# QN908XC register map
Vendor: nxp.com; File version: 1.0
CPU: CM4 r0p1, little endian, no MPU, no FPU, 0x3 interrupt priority bits, 0x0 interrupts
Registers are 32-bit, read-write, reset 0x0 unless marked. A register's access mark holds for its fields unless they carry their own. Offsets are from the block's base; [hi:lo] are bit positions; {n}, {i} and the like mark numbered series; 'fields as' and 'values as' point back to an identical list; <NAME> marks a mode.

## ADC
Base 0x40007000
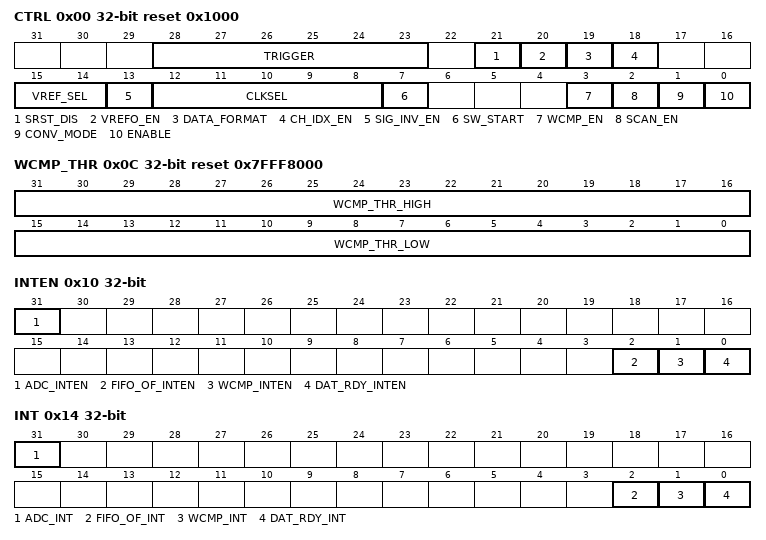
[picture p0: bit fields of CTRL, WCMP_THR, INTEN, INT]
0x00 CTRL reset 0x1000 (reset mask 0x1FBCFF0F) — ADC control register
  [28:23] TRIGGER — Adc start trigger. 0 to 31 PA00 to PA31; 32 to 34 GPIOB0 to GPIOB2; 35, software trigger; 36, rng trigger; 56 to 59, timer 0 to timer 3; 60 to 63 pwm 0 to pwm 3
  [21] SRST_DIS — 1 to disable adc reset.
  [20] VREFO_EN — 1 to enable bandgap out-chip capacitor
  [19] DATA_FORMAT — Data output format. When DATA_FORMAT ==0, When CH_IDX_EN ==0, the ADC_DATA[31:0] is adc data, signed data, 31 bit frac. When CH_IDX_EN ==1, the ADC_DATA[4:0] is channel output, {ADC_DATA[31:5],5'h0} is adc data, signed data, 31 bit frac. When DATA_FORMAT ==1, When CH_IDX_EN ==0, the ADC_DATA[22:0] is adc data, signed data, 22 bit frac. When CH_IDX_EN ==1, the ADC_DATA[31:27] is channel output, ADC_DATA[22:0] is adc data, signed data, 22 bit frac.
  [18] CH_IDX_EN — 1 to append channel index in data result to be used in scan mode
  [15:14] VREF_SEL — Sigma-Delta ADC Reference source selection.
    0=INT_1P2V (Internal vref 1.2V); 1=EXT_DRV (External VREF); 2=EXT_NO_DRV (Vext without driver); 3=VCC
  [13] SIG_INV_EN — 1 to invert Signma-Delta input signal
  [12:8] CLKSEL — Sigma-Delta ADC clock select
    0=CLKSEL_31P25K (31P25K); 4=CLKSEL_62P5K (62P5K); 8=CLKSEL_125K (125K); 12=CLKSEL_250K (250K); 16=CLKSEL_500K (500K); 20=CLKSEL_1M (1M); 24=CLKSEL_2M (2M); 29=CLKSEL_32K (32K)
  [7] SW_START wo — Software start ADC conversion write1 to trigger one time ADC conversion, no need clear.
  [3] WCMP_EN — 1 to enable window compare
  [2] SCAN_EN — 1 to enable scan mode
  [1] CONV_MODE — ADC conversion mode
    0=BURST (burst conversion); 1=SINGLE (single conversion)
  [0] ENABLE — ADC enable. Write 1 to Writing 1 before starting conversion and 0 to end conversion.
0x04 CH_SEL reset 0x1 — ADC channel selection register
  [31:0] CH_SEL — In scan conversion mode, the channels with 1 set will be scanned, from LSB to MSB. In none scan conversion mode, only the first channel from LSB with 1 set will be converted. If all bits are set to 0, no ADC conversion will be started.
0x08 CH_CFG — ADC channel configuration register
  [31:0] CH_CFG — whenCH_CONFIG[N] is 0, the N channelwill select the configure 0 option(seeregister SD_CONFIG0). whenCH_CONFIG[N] is 1, the N channelwill select the configure 1 option(seeregister SD_CONFIG1).
0x0C WCMP_THR reset 0x7FFF8000 — Window compare threshold register
  [31:16] WCMP_THR_HIGH — <s 0 15> Windows compare high threshold If ADC decimation result is out of the window one compare interrupt will be triggered.
  [15:0] WCMP_THR_LOW — <s 0 15> Windows compare low threshold.
0x10 INTEN — ADC interrupt enable register
  [31] ADC_INTEN — 1 to enable ADC interrupt
  [2] FIFO_OF_INTEN — 1 to enalble FIFO overflow interrupt.
  [1] WCMP_INTEN — 1 to enable Window compare interrupt.
  [0] DAT_RDY_INTEN — 1 to enable Data ready interrupt
0x14 INT — ADC interrupt status register
  [31] ADC_INT ro — ADC interrupt.
  [2] FIFO_OF_INT write-1-clears — FIFO overflow interrupt.
  [1] WCMP_INT write-1-clears — Window compare interrupt.
  [0] DAT_RDY_INT ro — Data ready interrupt will be cleared after fifo data is read can not be cleared by write 1.
0x18 DATA ro — ADC converted data output
  [31:0] DATA — ADC data read from FIFO.
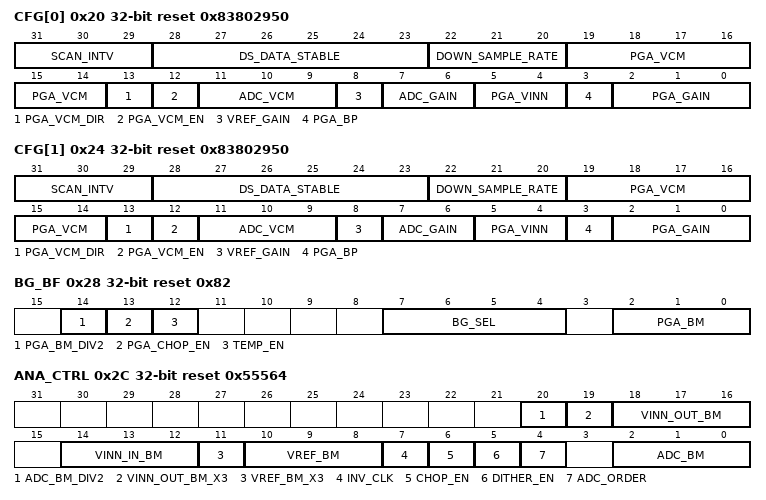
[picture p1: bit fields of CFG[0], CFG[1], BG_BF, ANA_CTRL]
0x20 CFG[0] reset 0x83802950 — ADC configuration register
  [31:29] SCAN_INTV — Interval when switching ADC source; 2/4/8/16/32/64/128/256 clock cycle.
    0=SCAN_INTV_2CLK (2 clock cycle); 1=SCAN_INTV_4CLK (4 clock cycle); 2=SCAN_INTV_8CLK (8 clock cycle); 3=SCAN_INTV_16CLK (16 clock cycle); 4=SCAN_INTV_32CLK (32 clock cycle); 5=SCAN_INTV_64CLK (64 clock cycle); 6=SCAN_INTV_128CLK (128 clock cycle); 7=SCAN_INTV_256CLK (256 clock cycle)
  [28:23] DS_DATA_STABLE — Down sample date stable number. you can keep the bit 1:0 to 2'b11. DS_DATA_STABLE0[5:2]+1
  [22:20] DOWN_SAMPLE_RATE
    1=DOWN_SAMPLE_32; 3=DOWN_SAMPLE_64; 4=DOWN_SAMPLE_256; 5=DOWN_SAMPLE_128
  [19:14] PGA_VCM — SD ADC PGA output common voltage, adjustment = (PGA_VCM0[5]+1)*(PGA_VCM0[3:0]+1)*40mv
  [13] PGA_VCM_DIR — SD ADC PGA output common voltage control direction signal.
    0=DOWN; 1=UP
  [12] PGA_VCM_EN — SD ADC PGA output common voltage control enable signal.
  [11:9] ADC_VCM — SD ADC input common voltage selection.
    0=ADC_VCM_1D16 (1/16 VCC); {v}=ADC_VCM_{v}D8 ({v}/8 VCC) (v=1..7)
  [8] VREF_GAIN — SD ADC Reference Gain seletion
    0=VREF_GAIN_1X (1x); 1=VREF_GAIN_1P5X (1.5x)
  [7:6] ADC_GAIN — SD ADC gain selection.
    0=ADC_GAIN_0P5X (0.5x); 1=ADC_GAIN_1X (1x); 2=ADC_GAIN_1P5X (1.5x); 3=ADC_GAIN_2X (2x)
  [5:4] PGA_VINN — SD ADC PGA VIN input offset selection
    0=VREF; 1=VREF_0P75 (3/4 VREF); 2=VREF_0P5 (1/2 VREF); 3=AVSS
  [3] PGA_BP — 1 to bypass SD ADC input PGA
  [2:0] PGA_GAIN — SD ADC input PGA gain=2^value the range is 1-16.
0x24 CFG[1] reset 0x83802950 — ADC configuration register
  fields as CFG[0]
0x28 BG_BF reset 0x82 (reset mask 0x30F7) — ADC bandcap and buffer setting register
  [14] PGA_BM_DIV2 — 1 to half PGA bias current
  [13] PGA_CHOP_EN — 1 to enable chopper in PGA
  [12] TEMP_EN — 1 to enable temperature sensor
  [7:4] BG_SEL — Bandgap voltage selection to compensate PVT variations8 steps with 5mV each upward. VBG=1205+5*BGSEL(mV)
  [2:0] PGA_BM — SD ADC buffer bias current selection.
    0=PGA_BM_50PCNT (50%); 1=PGA_BM_75PCNT (75%); 2=PGA_BM_100PCNT (100%); 3=PGA_BM_150PCNT (150%); 4=PGA_BM_200PCNT (200%); 5=PGA_BM_300PCNT (300%)
0x2C ANA_CTRL reset 0x55564 (reset mask 0xF77F7) — ADC core and reference setting regsiter
  [20] ADC_BM_DIV2 — SD ADC bias current half.
  [19] VINN_OUT_BM_X3 — PGA VlNN Output Driver bias current triple.
  [18:16] VINN_OUT_BM — PGA VlNN Output Driver bias current selection.
    0=VINN_OUT_BM_50PCNT (50%); 1=VINN_OUT_BM_75PCNT (75%); 2=VINN_OUT_BM_100PCNT (100%); 3=VINN_OUT_BM_150PCNT (150%); 4=VINN_OUT_BM_200PCNT (200%); 5=VINN_OUT_BM_300PCNT (300%)
  [14:12] VINN_IN_BM — PGA VlNN Input Driver bias current selection.
    0=VINN_IN_BM_50PCNT (50%); 1=VINN_IN_BM_75PCNT (75%); 2=VINN_IN_BM_100PCNT (100%); 3=VINN_IN_BM_150PCNT (150%); 4=VINN_IN_BM_200PCNT (200%); 5=VINN_IN_BM_300PCNT (300%)
  [11] VREF_BM_X3 — SD ADC Reference Driver bias current triple.
  [10:8] VREF_BM — SD ADC Reference Driver bias current selection.
    0=VREF_BM_50PCNT (50%); 1=VREF_BM_75PCNT (75%); 2=VREF_BM_100PCNT (100%); 3=VREF_BM_150PCNT (150%); 4=VREF_BM_200PCNT (200%); 5=VREF_BM_300PCNT (300%)
  [7] INV_CLK — 1 to invert SD ADC Output Clock
  [6] CHOP_EN — 1 to enable SD ADC chopper
  [5] DITHER_EN — 1 to enable SD ADC PN Sequence in chopper mode
  [4] ADC_ORDER — 1 to enable SD ADC 2 order mode selection
    0=ADC_ORDER_3ORDER (3 order); 1=ADC_ORDER_2ORDER (2 order)
  [2:0] ADC_BM — ADC bias current selection.
    0=ADC_BM_50PCNT (50%); 1=ADC_BM_75PCNT (75%); 2=ADC_BM_100PCNT (100%); 3=ADC_BM_150PCNT (150%); 4=ADC_BM_200PCNT (200%); 5=ADC_BM_300PCNT (300%)
